# LargeDummyDevice register map
File version: 1.0
Registers are 32-bit, read-write, no defined reset value unless marked. A register's access mark holds for its fields unless they carry their own. Offsets are from the block's base; [hi:lo] are bit positions.

## PERIPHERAL_39
Base 0x40026000
0x04 REG_1 — Register 1
  [29] FIELD_4, [30:29] FIELD_5, [31:28] FIELD_14, [28] FIELD_25, [26:25] FIELD_11, [25:23] FIELD_1, [23:19] FIELD_23, [18] FIELD_7, [20:17] FIELD_13, [17] FIELD_20, [18:16] FIELD_9, [17:16] FIELD_16, [19:15] FIELD_22, [15:14] FIELD_15, [15:13] FIELD_2, [16:13] FIELD_17, [15:12] FIELD_12, [15:12] FIELD_21, [9] FIELD_19, [11:8] FIELD_10, [8] FIELD_24, [11:7] FIELD_8, [10:6] FIELD_27, [5] FIELD_6, [4] FIELD_3, [7:4] FIELD_26, [4:1] FIELD_18
0x08 REG_2 — Register 2
  [30:27] FIELD_7, [29:26] FIELD_2, [24] FIELD_8, [25:23] FIELD_11, [25:21] FIELD_6, [22:21] FIELD_15, [22:19] FIELD_9, [20:19] FIELD_10, [15] FIELD_5, [18:15] FIELD_14, [17:15] FIELD_16, [14:11] FIELD_13, [12:10] FIELD_4, [8] FIELD_3, [8:7] FIELD_1, [5:2] FIELD_12
0x0C REG_3 — Register 3
  [33:31] FIELD_2, [29] FIELD_1, [31:27] FIELD_19, [30:26] FIELD_4, [30:26] FIELD_22, [24] FIELD_25, [24:22] FIELD_3, [23:22] FIELD_9, [25:22] FIELD_10, [22:21] FIELD_15, [22:19] FIELD_12, [21:19] FIELD_17, [19] FIELD_24, [19:17] FIELD_16, [20:16] FIELD_5, [16:14] FIELD_6, [18:14] FIELD_7, [11] FIELD_11, [11:8] FIELD_27, [10:7] FIELD_20, [11:7] FIELD_26, [9:6] FIELD_13, [8:5] FIELD_8, [6:4] FIELD_14, [4:3] FIELD_23, [2] FIELD_18, [4:2] FIELD_28, [1] FIELD_21
0x10 REG_4 — Register 4
  [33:30] FIELD_1, [30:29] FIELD_25, [29:28] FIELD_14, [27] FIELD_16, [25] FIELD_2, [23:22] FIELD_4, [23:22] FIELD_20, [25:22] FIELD_22, [25:21] FIELD_28, [24:20] FIELD_12, [23:19] FIELD_21, [22:18] FIELD_13, [20:16] FIELD_17, [18:15] FIELD_10, [19:15] FIELD_29, [16:13] FIELD_15, [15:13] FIELD_24, [12] FIELD_7, [14:12] FIELD_23, [12:11] FIELD_5, [13:11] FIELD_19, [11:9] FIELD_26, [11:7] FIELD_18, [8:6] FIELD_3, [10:6] FIELD_6, [5] FIELD_9, [7:4] FIELD_11, [4] FIELD_27, [6:2] FIELD_8
0x14 REG_5 — Register 5
  [33:30] FIELD_5, [31:29] FIELD_4, [29:27] FIELD_6, [30:27] FIELD_12, [29:27] FIELD_28, [25] FIELD_7, [25:23] FIELD_20, [23] FIELD_22, [22] FIELD_11, [22:20] FIELD_2, [21:19] FIELD_19, [21:18] FIELD_17, [21:17] FIELD_13, [20:16] FIELD_9, [16:15] FIELD_14, [17:15] FIELD_31, [17:14] FIELD_25, [15:14] FIELD_30, [13] FIELD_29, [11] FIELD_18, [12:9] FIELD_23, [11:9] FIELD_24, [12:8] FIELD_15, [11:8] FIELD_21, [9:6] FIELD_1, [8:6] FIELD_27, [5] FIELD_3, [8:4] FIELD_8, [8:4] FIELD_10, [6:4] FIELD_26, [1:0] FIELD_16
0x18 REG_6 — Register 6
  [32:29] FIELD_15, [25] FIELD_1, [25:24] FIELD_6, [20:18] FIELD_9, [19:17] FIELD_2, [17:16] FIELD_5, [14] FIELD_14, [14:13] FIELD_11, [13:12] FIELD_12, [13:9] FIELD_3, [11:8] FIELD_8, [8:7] FIELD_10, [10:6] FIELD_4, [8:6] FIELD_7, [5:1] FIELD_13
0x1C REG_7 — Register 7
  [31] FIELD_17, [31:30] FIELD_9, [31:30] FIELD_19, [30:29] FIELD_8, [32:29] FIELD_20, [27:26] FIELD_15, [26] FIELD_21, [26:25] FIELD_3, [26:25] FIELD_18, [28:24] FIELD_11, [25:21] FIELD_7, [22:20] FIELD_27, [19:17] FIELD_25, [18:16] FIELD_29, [16:15] FIELD_23, [17:14] FIELD_1, [14] FIELD_5, [18:14] FIELD_6, [15:14] FIELD_22, [12] FIELD_4, [13:10] FIELD_28, [11:9] FIELD_13, [13:9] FIELD_26, [10:8] FIELD_10, [11:8] FIELD_12, [10:6] FIELD_16, [8:5] FIELD_14, [4:2] FIELD_24, [1] FIELD_2
0x20 REG_8 — Register 8
  [34:31] FIELD_14, [30] FIELD_15, [28:27] FIELD_12, [25:24] FIELD_16, [24:22] FIELD_6, [22:21] FIELD_11, [21:20] FIELD_3, [21:19] FIELD_5, [17] FIELD_4, [18:15] FIELD_2, [15] FIELD_19, [13] FIELD_10, [14:10] FIELD_8, [10:9] FIELD_7, [10:7] FIELD_20, [3] FIELD_13, [6:3] FIELD_17, [2:1] FIELD_9, [5:1] FIELD_18, [0] FIELD_1, [3:0] FIELD_21
0x24 REG_9 — Register 9
  [32:30] FIELD_7, [31:30] FIELD_22, [33:29] FIELD_27, [27:26] FIELD_8, [28:26] FIELD_20, [26:25] FIELD_14, [26:25] FIELD_17, [25:24] FIELD_28, [22] FIELD_3, [24:21] FIELD_11, [21:20] FIELD_23, [21:19] FIELD_12, [21:18] FIELD_10, [21:17] FIELD_21, [18:15] FIELD_5, [11] FIELD_25, [11:10] FIELD_19, [13:9] FIELD_13, [10:8] FIELD_4, [11:7] FIELD_24, [10:7] FIELD_29, [6:5] FIELD_1, [9:5] FIELD_30, [8:4] FIELD_16, [5:2] FIELD_2, [6:2] FIELD_31, [5:1] FIELD_6, [1] FIELD_15, [1:0] FIELD_9, [2:0] FIELD_18, [2:0] FIELD_26
0x28 REG_10 — Register 10
  [31:30] FIELD_6, [33:29] FIELD_2, [32:29] FIELD_4, [28:26] FIELD_3, [21:17] FIELD_5, [10:9] FIELD_1
0x2C REG_11 — Register 11
  [33:31] FIELD_11, [35:31] FIELD_18, [34:30] FIELD_9, [30:29] FIELD_19, [31:28] FIELD_12, [25] FIELD_2, [25:24] FIELD_24, [26:23] FIELD_5, [25:23] FIELD_8, [27:23] FIELD_26, [22] FIELD_16, [21] FIELD_1, [20:16] FIELD_10, [17:16] FIELD_14, [17:16] FIELD_17, [20:16] FIELD_22, [17:15] FIELD_20, [15] FIELD_27, [18:14] FIELD_4, [17:14] FIELD_21, [15:13] FIELD_3, [14:12] FIELD_15, [14:12] FIELD_28, [13:11] FIELD_6, [10] FIELD_23, [13:9] FIELD_13, [7:6] FIELD_7, [4:0] FIELD_25
0x30 REG_12 — Register 12
  [33:31] FIELD_5, [34:31] FIELD_20, [33:30] FIELD_12, [34:30] FIELD_13, [33:30] FIELD_15, [31:29] FIELD_8, [32:28] FIELD_16, [30:26] FIELD_3, [28:26] FIELD_9, [27:26] FIELD_18, [27:24] FIELD_11, [20:18] FIELD_17, [18] FIELD_21, [18:16] FIELD_2, [19:15] FIELD_19, [15:14] FIELD_10, [16:13] FIELD_4, [10] FIELD_14, [9:7] FIELD_1, [8:7] FIELD_7, [2] FIELD_6
0x34 REG_13 — Register 13
  [31:30] FIELD_8, [30:27] FIELD_2, [25:24] FIELD_1, [24:22] FIELD_15, [21] FIELD_20, [22:20] FIELD_5, [23:20] FIELD_22, [20:18] FIELD_17, [17] FIELD_3, [18:17] FIELD_7, [17] FIELD_19, [16:13] FIELD_9, [17:13] FIELD_13, [12:9] FIELD_14, [9:7] FIELD_10, [9:7] FIELD_18, [10:6] FIELD_12, [7:5] FIELD_4, [7:5] FIELD_11, [8:5] FIELD_23, [5:4] FIELD_16, [4:3] FIELD_21, [3:0] FIELD_6, [3:0] FIELD_24
0x38 REG_14 — Register 14
  [32:30] FIELD_11, [34:30] FIELD_14, [29] FIELD_8, [28:27] FIELD_1, [24:23] FIELD_4, [23] FIELD_6, [24:23] FIELD_13, [22] FIELD_3, [23:20] FIELD_2, [14:10] FIELD_5, [5] FIELD_7, [5:3] FIELD_12, [3] FIELD_15, [5:2] FIELD_10, [2:0] FIELD_9
0x3C REG_15 — Register 15
  [34:31] FIELD_5, [30] FIELD_8, [30] FIELD_26, [30:29] FIELD_28, [30:28] FIELD_14, [28:27] FIELD_24, [25] FIELD_9, [26:22] FIELD_13, [21] FIELD_27, [20] FIELD_22, [19] FIELD_7, [20:19] FIELD_19, [18:16] FIELD_3, [18:16] FIELD_12, [16] FIELD_15, [19:16] FIELD_17, [17:16] FIELD_21, [15] FIELD_1, [12] FIELD_10, [11:10] FIELD_2, [10:8] FIELD_20, [8:7] FIELD_23, [9:7] FIELD_25, [6] FIELD_6, [5:4] FIELD_11, [3:2] FIELD_4, [6:2] FIELD_16, [4:0] FIELD_18
0x40 REG_16 — Register 16
  [32:29] FIELD_1, [28:24] FIELD_6, [25:23] FIELD_8, [24:21] FIELD_10, [21:18] FIELD_4, [20:18] FIELD_5, [20:16] FIELD_2, [12:9] FIELD_7, [9:5] FIELD_9, [6:4] FIELD_3
0x44 REG_17 — Register 17
  [29:27] FIELD_7, [28:24] FIELD_3, [25:23] FIELD_5, [21:20] FIELD_4, [16:12] FIELD_6, [13:9] FIELD_2, [8:4] FIELD_1
0x48 REG_18 — Register 18
  [31] FIELD_15, [32:31] FIELD_21, [34:30] FIELD_5, [31:28] FIELD_1, [26:24] FIELD_6, [22:20] FIELD_2, [18:17] FIELD_4, [18:17] FIELD_29, [18:16] FIELD_27, [18:16] FIELD_30, [18:15] FIELD_8, [18:15] FIELD_26, [16:14] FIELD_20, [14:13] FIELD_7, [15:13] FIELD_13, [13:11] FIELD_16, [9] FIELD_14, [9:8] FIELD_17, [10:8] FIELD_18, [11:8] FIELD_24, [10:8] FIELD_25, [7:6] FIELD_10, [7:5] FIELD_22, [8:4] FIELD_9, [7:4] FIELD_11, [6:4] FIELD_12, [5:4] FIELD_28, [1] FIELD_19, [4:0] FIELD_3, [0] FIELD_23
0x4C REG_19 — Register 19
  [34:30] FIELD_15, [30] FIELD_30, [29] FIELD_8, [30:29] FIELD_17, [32:28] FIELD_10, [28:27] FIELD_25, [27:26] FIELD_16, [23] FIELD_4, [26:23] FIELD_9, [25:23] FIELD_21, [24:23] FIELD_23, [22] FIELD_1, [20] FIELD_11, [23:20] FIELD_20, [20] FIELD_29, [22:18] FIELD_13, [18:17] FIELD_3, [18:14] FIELD_18, [16:13] FIELD_5, [12] FIELD_6, [16:12] FIELD_19, [15:12] FIELD_31, [11] FIELD_26, [11:10] FIELD_27, [12:8] FIELD_2, [6] FIELD_28, [7:5] FIELD_22, [8:4] FIELD_14, [3] FIELD_7, [7:3] FIELD_24, [3:2] FIELD_12
0x50 REG_20 — Register 20
  [31:30] FIELD_2, [32:30] FIELD_3, [27:25] FIELD_5, [20:17] FIELD_4, [18:15] FIELD_8, [13:11] FIELD_11, [11:10] FIELD_9, [12:10] FIELD_12, [11:9] FIELD_7, [12:8] FIELD_1, [8:4] FIELD_10, [4:2] FIELD_6, [5:1] FIELD_13
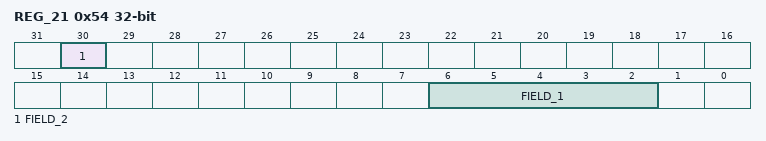
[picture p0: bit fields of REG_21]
0x54 REG_21 — Register 21
  [30] FIELD_2, [6:2] FIELD_1
0x58 REG_22 — Register 22
  [33:30] FIELD_8, [33:29] FIELD_12, [31:28] FIELD_5, [30:28] FIELD_14, [28:26] FIELD_16, [29:25] FIELD_10, [29:25] FIELD_20, [18] FIELD_13, [21:18] FIELD_15, [21:17] FIELD_4, [19:17] FIELD_7, [16] FIELD_6, [14] FIELD_1, [18:14] FIELD_18, [12] FIELD_3, [11:10] FIELD_19, [10:8] FIELD_17, [7:6] FIELD_2, [3] FIELD_9, [1:0] FIELD_11
0x5C REG_23 — Register 23
  [34:31] FIELD_4, [32:31] FIELD_12, [35:31] FIELD_14, [30] FIELD_13, [32:28] FIELD_2, [32:28] FIELD_9, [30:28] FIELD_27, [27:25] FIELD_21, [26:24] FIELD_24, [23] FIELD_7, [23:20] FIELD_15, [19] FIELD_8, [23:19] FIELD_11, [20:19] FIELD_19, [19:18] FIELD_23, [19:17] FIELD_5, [18:15] FIELD_20, [16:15] FIELD_22, [14] FIELD_26, [16:13] FIELD_18, [15:13] FIELD_25, [11:10] FIELD_10, [9] FIELD_17, [8:5] FIELD_6, [7:4] FIELD_1, [6:4] FIELD_16, [6:3] FIELD_3
0x60 REG_24 — Register 24
  [35:31] FIELD_8, [34:31] FIELD_12, [35:31] FIELD_18, [33:30] FIELD_16, [28:26] FIELD_6, [27:26] FIELD_23, [24] FIELD_4, [25:24] FIELD_13, [23:19] FIELD_3, [21:19] FIELD_21, [22:18] FIELD_1, [17] FIELD_19, [18:16] FIELD_22, [17:14] FIELD_14, [16:12] FIELD_2, [16:12] FIELD_24, [15:11] FIELD_10, [12:11] FIELD_15, [10] FIELD_11, [11:9] FIELD_17, [8:7] FIELD_9, [3] FIELD_5, [7:3] FIELD_20, [1:0] FIELD_7
0x64 REG_25 — Register 25
  [31] FIELD_5, [31:27] FIELD_15, [27:25] FIELD_2, [24:23] FIELD_8, [25:21] FIELD_6, [16:15] FIELD_3, [15] FIELD_13, [11:9] FIELD_4, [13:9] FIELD_12, [10:6] FIELD_14, [7:4] FIELD_1, [4:3] FIELD_7, [4:3] FIELD_9, [7:3] FIELD_10, [5:2] FIELD_11
0x68 REG_26 — Register 26
  [35:31] FIELD_3, [35:31] FIELD_4, [30] FIELD_17, [33:30] FIELD_20, [30:29] FIELD_30, [27:26] FIELD_27, [29:25] FIELD_12, [24] FIELD_2, [25:23] FIELD_7, [26:23] FIELD_31, [23:21] FIELD_24, [19:18] FIELD_8, [19:18] FIELD_13, [18] FIELD_18, [19:16] FIELD_23, [17:15] FIELD_6, [17:15] FIELD_22, [15] FIELD_28, [14:12] FIELD_19, [16:12] FIELD_32, [12:11] FIELD_10, [11] FIELD_25, [13:11] FIELD_26, [10:8] FIELD_29, [7] FIELD_1, [6:5] FIELD_5, [6:4] FIELD_14, [5:4] FIELD_15, [4] FIELD_16, [5:3] FIELD_11, [3:1] FIELD_9, [3:0] FIELD_21
0x6C REG_27 — Register 27
  [31] FIELD_4, [25:24] FIELD_3, [24:22] FIELD_5, [23:20] FIELD_2, [22:19] FIELD_6, [23:19] FIELD_7, [18:14] FIELD_8, [10] FIELD_1
0x70 REG_28 — Register 28
  [35:31] FIELD_2, [21] FIELD_1, [20] FIELD_7, [22:19] FIELD_3, [21:18] FIELD_6, [7:3] FIELD_5, [1] FIELD_4
0x74 REG_29 — Register 29
  [30:29] FIELD_2, [23:21] FIELD_7, [17:15] FIELD_4, [16:14] FIELD_6, [13:10] FIELD_5, [7:3] FIELD_1, [2] FIELD_3
0x78 REG_30 — Register 30
  [30:27] FIELD_6, [18] FIELD_3, [13] FIELD_4, [8] FIELD_1, [10:8] FIELD_5, [1:0] FIELD_2
0x7C REG_31 — Register 31
  [32:31] FIELD_8, [33:31] FIELD_20, [32:31] FIELD_25, [32:29] FIELD_22, [29:27] FIELD_24, [24:23] FIELD_26, [21:20] FIELD_2, [20:18] FIELD_16, [17] FIELD_5, [17:16] FIELD_11, [18:15] FIELD_13, [18:15] FIELD_21, [13:12] FIELD_17, [13:12] FIELD_19, [12:9] FIELD_9, [7:6] FIELD_7, [5:4] FIELD_23, [3] FIELD_3, [4:2] FIELD_1, [3:1] FIELD_6, [3:1] FIELD_10, [5:1] FIELD_12, [4:1] FIELD_14, [2:1] FIELD_15, [2:0] FIELD_4, [1:0] FIELD_18
0x80 REG_32 — Register 32
  [25:23] FIELD_4, [23:22] FIELD_5, [19] FIELD_6, [18:17] FIELD_1, [15:13] FIELD_9, [8:7] FIELD_7, [6:4] FIELD_3, [5:3] FIELD_2, [3:1] FIELD_8
0x84 REG_33 — Register 33
  [32:31] FIELD_1, [28] FIELD_12, [30:28] FIELD_14, [30:28] FIELD_16, [31:28] FIELD_22, [28:26] FIELD_25, [27:23] FIELD_13, [26:22] FIELD_5, [24:21] FIELD_7, [21:18] FIELD_10, [20:17] FIELD_6, [19:17] FIELD_9, [16:15] FIELD_18, [15] FIELD_21, [16:13] FIELD_24, [15:11] FIELD_15, [10] FIELD_19, [9] FIELD_3, [10:8] FIELD_8, [8:6] FIELD_11, [9:6] FIELD_20, [9:5] FIELD_17, [5:1] FIELD_4, [0] FIELD_2, [1:0] FIELD_23, [0] FIELD_26
0x88 REG_34 — Register 34
  [34:30] FIELD_3, [32:30] FIELD_20, [30:29] FIELD_12, [27:23] FIELD_15, [24:22] FIELD_7, [23:21] FIELD_21, [21:19] FIELD_8, [19:17] FIELD_6, [18:15] FIELD_2, [14] FIELD_13, [17:13] FIELD_24, [16:12] FIELD_19, [16:12] FIELD_25, [11] FIELD_11, [11:10] FIELD_23, [9:8] FIELD_16, [8:7] FIELD_14, [8:7] FIELD_22, [6:5] FIELD_18, [7:4] FIELD_9, [7:3] FIELD_5, [5:1] FIELD_1, [4:1] FIELD_4, [3:1] FIELD_17, [0] FIELD_10
0x8C REG_35 — Register 35
  [30] FIELD_16, [31:28] FIELD_13, [25] FIELD_2, [27:25] FIELD_8, [28:24] FIELD_20, [25:22] FIELD_18, [22:21] FIELD_15, [21] FIELD_19, [20] FIELD_1, [19:16] FIELD_7, [18:14] FIELD_10, [15:13] FIELD_3, [13] FIELD_5, [15:11] FIELD_14, [9] FIELD_9, [9:7] FIELD_12, [7:5] FIELD_4, [7:5] FIELD_17, [7:4] FIELD_6, [4] FIELD_21, [3:2] FIELD_11
0x90 REG_36 — Register 36
  [19:15] FIELD_3, [15:14] FIELD_1, [3] FIELD_2
0x94 REG_37 — Register 37
  [27:26] FIELD_5, [26:25] FIELD_10, [12:11] FIELD_1, [12:9] FIELD_9, [8:5] FIELD_6, [5:2] FIELD_4, [2] FIELD_7, [2:1] FIELD_2, [3:1] FIELD_3, [4:1] FIELD_8, [4:1] FIELD_11
0x98 REG_38 — Register 38
  [31:30] FIELD_4, [31:29] FIELD_7, [27:25] FIELD_11, [22] FIELD_13, [19] FIELD_6, [18] FIELD_9, [20:17] FIELD_2, [18:15] FIELD_8, [13:10] FIELD_12, [7:4] FIELD_5, [3] FIELD_1, [1] FIELD_10, [2:0] FIELD_3
0x9C REG_39 — Register 39
  [32:30] FIELD_1, [31:30] FIELD_2, [29:28] FIELD_22, [28:27] FIELD_25, [26] FIELD_20, [26:25] FIELD_4, [29:25] FIELD_17, [29:25] FIELD_24, [27:24] FIELD_15, [27:23] FIELD_7, [23:21] FIELD_8, [21:20] FIELD_10, [20] FIELD_21, [20:19] FIELD_14, [20:17] FIELD_11, [15] FIELD_5, [19:15] FIELD_6, [16:14] FIELD_12, [16:14] FIELD_19, [13] FIELD_18, [13:10] FIELD_23, [13:9] FIELD_13, [9] FIELD_27, [11:8] FIELD_16, [6] FIELD_26, [7:4] FIELD_9, [1] FIELD_3
0xA0 REG_40 — Register 40
  [33:30] FIELD_14, [25:22] FIELD_1, [25:22] FIELD_5, [19:17] FIELD_12, [15] FIELD_3, [16:12] FIELD_16, [11] FIELD_6, [15:11] FIELD_7, [11:10] FIELD_4, [10] FIELD_9, [10:6] FIELD_15, [6:3] FIELD_11, [6:3] FIELD_13, [5:1] FIELD_2, [1:0] FIELD_8, [0] FIELD_10
0xA4 REG_41 — Register 41
  [31:28] FIELD_17, [32:28] FIELD_18, [26:24] FIELD_10, [26:24] FIELD_14, [27:23] FIELD_8, [23] FIELD_13, [25:21] FIELD_2, [21] FIELD_5, [23:21] FIELD_12, [15] FIELD_16, [14] FIELD_9, [17:13] FIELD_1, [16:12] FIELD_11, [8:7] FIELD_7, [7:6] FIELD_15, [8:5] FIELD_4, [4:2] FIELD_3, [0] FIELD_6
0xA8 REG_42 — Register 42
  [31:27] FIELD_10, [25:23] FIELD_2, [21] FIELD_1, [21:18] FIELD_4, [19:15] FIELD_6, [9] FIELD_7, [10:8] FIELD_9, [9:7] FIELD_5, [8:6] FIELD_11, [3:1] FIELD_3, [2:1] FIELD_8
0xAC REG_43 — Register 43
  [29:28] FIELD_12, [32:28] FIELD_16, [28:25] FIELD_8, [25] FIELD_19, [24:23] FIELD_13, [25:21] FIELD_2, [20] FIELD_1, [21:17] FIELD_15, [16] FIELD_27, [15] FIELD_5, [18:15] FIELD_22, [15] FIELD_26, [18:14] FIELD_6, [17:13] FIELD_24, [15:12] FIELD_10, [16:12] FIELD_18, [13:11] FIELD_7, [13:11] FIELD_17, [12:11] FIELD_28, [13:10] FIELD_29, [13:9] FIELD_3, [10:9] FIELD_11, [10:9] FIELD_23, [13:9] FIELD_31, [11:8] FIELD_4, [12:8] FIELD_14, [8:4] FIELD_30, [6:3] FIELD_21, [3] FIELD_25, [4:2] FIELD_20, [1:0] FIELD_9
0xB0 REG_44 — Register 44
  [32:30] FIELD_10, [28] FIELD_16, [30:26] FIELD_4, [27:25] FIELD_7, [23:22] FIELD_3, [24:21] FIELD_6, [19] FIELD_12, [21:18] FIELD_1, [17:15] FIELD_17, [18:14] FIELD_11, [16:13] FIELD_14, [16:13] FIELD_15, [15:12] FIELD_2, [14:12] FIELD_5, [5:3] FIELD_8, [4:3] FIELD_13, [3:1] FIELD_9
0xB4 REG_45 — Register 45
  [33:31] FIELD_1, [35:31] FIELD_4, [31:30] FIELD_9, [24] FIELD_3, [27:24] FIELD_15, [18] FIELD_14, [17:15] FIELD_12, [14:13] FIELD_5, [13] FIELD_8, [12] FIELD_10, [12:11] FIELD_13, [14:10] FIELD_2, [10:6] FIELD_11, [6:5] FIELD_6, [5:4] FIELD_7
0xB8 REG_46 — Register 46
  [12:8] FIELD_1
0xBC REG_47 — Register 47
  [30] FIELD_1, [32:29] FIELD_6, [28] FIELD_8, [28:24] FIELD_5, [9:7] FIELD_4, [5:4] FIELD_3, [1] FIELD_2, [2:1] FIELD_7
0xC0 REG_48 — Register 48
  [32:31] FIELD_13, [31] FIELD_16, [31:30] FIELD_11, [34:30] FIELD_29, [31:29] FIELD_25, [31:28] FIELD_10, [31:28] FIELD_28, [32:28] FIELD_31, [27] FIELD_3, [30:27] FIELD_7, [24] FIELD_14, [24:22] FIELD_18, [22] FIELD_23, [24:21] FIELD_6, [22:18] FIELD_1, [18:16] FIELD_2, [16] FIELD_15, [17:15] FIELD_8, [15:14] FIELD_9, [12] FIELD_12, [12] FIELD_32, [14:11] FIELD_22, [11:10] FIELD_24, [14:10] FIELD_26, [12:9] FIELD_30, [9:8] FIELD_17, [5:4] FIELD_19, [8:4] FIELD_20, [4] FIELD_21, [5:2] FIELD_4, [3:2] FIELD_27, [3:0] FIELD_5
0xC4 REG_49 — Register 49
  [26:25] FIELD_1, [25:24] FIELD_3, [8:7] FIELD_2
0xC8 REG_50 — Register 50
  [35:31] FIELD_1, [33:30] FIELD_25, [30:27] FIELD_26, [28:26] FIELD_2, [29:26] FIELD_19, [27:25] FIELD_3, [28:24] FIELD_11, [24:22] FIELD_4, [26:22] FIELD_8, [20] FIELD_15, [24:20] FIELD_16, [18] FIELD_5, [21:17] FIELD_14, [18:17] FIELD_21, [19:16] FIELD_6, [20:16] FIELD_10, [16:15] FIELD_7, [16:13] FIELD_22, [13] FIELD_23, [14:11] FIELD_9, [12:11] FIELD_17, [10] FIELD_31, [10:9] FIELD_12, [10:9] FIELD_30, [8] FIELD_28, [9:7] FIELD_18, [10:7] FIELD_29, [6] FIELD_20, [10:6] FIELD_24, [8:5] FIELD_27, [3] FIELD_13
